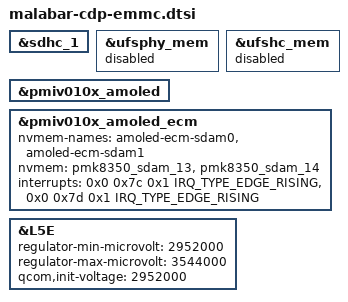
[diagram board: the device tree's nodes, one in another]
// SPDX-License-Identifier: BSD-3-Clause
/*
 * Copyright (c) Qualcomm Technologies, Inc. and/or its subsidiaries.
 */

#include "malabar-cdp.dtsi"
#include "malabar-pmiv010x.dtsi"

&sdhc_1 {
	status = "ok";
};

&ufsphy_mem {
	status = "disabled";
};

&ufshc_mem {
	status = "disabled";
};

&pmiv010x_amoled {
	status = "ok";
};

&pmiv010x_amoled_ecm {
	status = "ok";
	nvmem-names = "amoled-ecm-sdam0", "amoled-ecm-sdam1";
	nvmem = <&pmk8350_sdam_13>, <&pmk8350_sdam_14>;
	interrupt-names = "ecm-sdam0", "ecm-sdam1";
	interrupts = <0x0 0x7c 0x1 IRQ_TYPE_EDGE_RISING>,
		     <0x0 0x7d 0x1 IRQ_TYPE_EDGE_RISING>;
};

&L5E {
	regulator-min-microvolt = <2952000>;
	regulator-max-microvolt = <3544000>;
	qcom,init-voltage = <2952000>;
};
